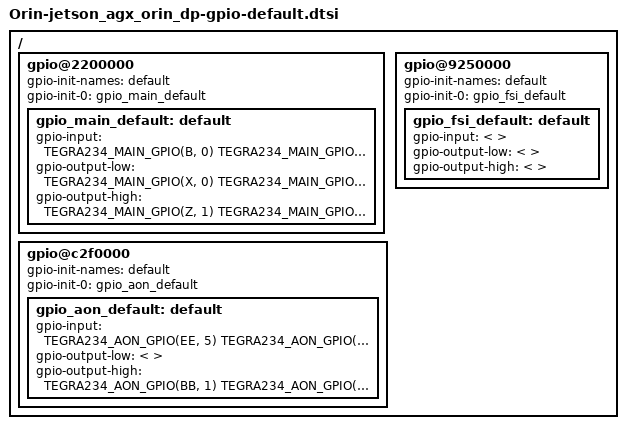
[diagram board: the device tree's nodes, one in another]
/*This dtsi file was generated by jetson_agx_orin_dp.xlsm Revision: 1,5 */
/*
 * Copyright (c) 2021, NVIDIA CORPORATION.  All rights reserved.
 *
 * This program is free software; you can redistribute it and/or modify
 * it under the terms of the GNU General Public License as published by
 * the Free Software Foundation; either version 2 of the License, or
 * (at your option) any later version.
 *
 * This program is distributed in the hope that it will be useful, but WITHOUT
 * ANY WARRANTY; without even the implied warranty of MERCHANTABILITY or
 * FITNESS FOR A PARTICULAR PURPOSE.  See the GNU General Public License for
 * more details.
 */

#include "tegra234-gpio.h"


/ {
	gpio@2200000 {
		gpio-init-names = "default";
		gpio-init-0 = <&gpio_main_default>;

		gpio_main_default: default {
			gpio-input = <
				TEGRA234_MAIN_GPIO(B, 0)
				TEGRA234_MAIN_GPIO(Q, 7)
				TEGRA234_MAIN_GPIO(R, 1)
				TEGRA234_MAIN_GPIO(N, 4)
				TEGRA234_MAIN_GPIO(N, 1)
				TEGRA234_MAIN_GPIO(G, 0)
				TEGRA234_MAIN_GPIO(G, 1)
				TEGRA234_MAIN_GPIO(G, 2)
				TEGRA234_MAIN_GPIO(G, 4)
				TEGRA234_MAIN_GPIO(G, 7)
				TEGRA234_MAIN_GPIO(AC, 4)
				TEGRA234_MAIN_GPIO(AC, 5)
				TEGRA234_MAIN_GPIO(K, 0)
				TEGRA234_MAIN_GPIO(K, 1)
				TEGRA234_MAIN_GPIO(K, 6)
				TEGRA234_MAIN_GPIO(K, 7)
				TEGRA234_MAIN_GPIO(L, 2)
				TEGRA234_MAIN_GPIO(L, 3)
				TEGRA234_MAIN_GPIO(AG, 0)
				TEGRA234_MAIN_GPIO(AG, 1)
				TEGRA234_MAIN_GPIO(AG, 2)
				TEGRA234_MAIN_GPIO(AG, 3)
				TEGRA234_MAIN_GPIO(AG, 6)
				TEGRA234_MAIN_GPIO(AG, 7)
				TEGRA234_MAIN_GPIO(AF, 2)
				TEGRA234_MAIN_GPIO(AF, 3)
				>;
			gpio-output-low = <
				TEGRA234_MAIN_GPIO(X, 0)
				TEGRA234_MAIN_GPIO(X, 1)
				TEGRA234_MAIN_GPIO(N, 3)
				TEGRA234_MAIN_GPIO(M, 5)
				TEGRA234_MAIN_GPIO(G, 5)
				TEGRA234_MAIN_GPIO(H, 3)
				TEGRA234_MAIN_GPIO(H, 6)
				TEGRA234_MAIN_GPIO(I, 5)
				TEGRA234_MAIN_GPIO(AC, 0)
				TEGRA234_MAIN_GPIO(AC, 1)
				TEGRA234_MAIN_GPIO(A, 1)
				TEGRA234_MAIN_GPIO(A, 2)
				>;
			gpio-output-high = <
				TEGRA234_MAIN_GPIO(Z, 1)
				TEGRA234_MAIN_GPIO(Q, 1)
				TEGRA234_MAIN_GPIO(K, 5)
				TEGRA234_MAIN_GPIO(A, 0)
				TEGRA234_MAIN_GPIO(A, 3)
				>;
		};
	};
	gpio@c2f0000 {
		gpio-init-names = "default";
		gpio-init-0 = <&gpio_aon_default>;

		gpio_aon_default: default {
			gpio-input = <
				TEGRA234_AON_GPIO(EE, 5)
				TEGRA234_AON_GPIO(EE, 6)
				TEGRA234_AON_GPIO(EE, 4)
				TEGRA234_AON_GPIO(CC, 0)
				TEGRA234_AON_GPIO(CC, 1)
				TEGRA234_AON_GPIO(CC, 2)
				TEGRA234_AON_GPIO(CC, 3)
				>;
			gpio-output-low = <
				>;
			gpio-output-high = <
				TEGRA234_AON_GPIO(BB, 1)
				TEGRA234_AON_GPIO(BB, 3)
				>;
		};
	};
	gpio@9250000 {
		gpio-init-names = "default";
		gpio-init-0 = <&gpio_fsi_default>;

		gpio_fsi_default: default {
			gpio-input = <
				>;
			gpio-output-low = <
				>;
			gpio-output-high = <
				>;
		};
	};

};
